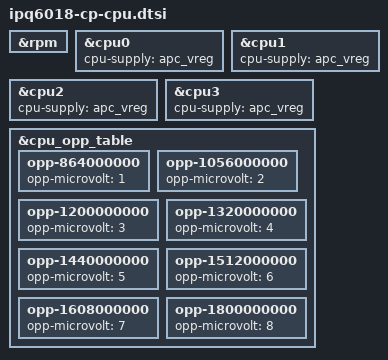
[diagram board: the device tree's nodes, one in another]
// SPDX-License-Identifier: GPL-2.0-or-later OR MIT

#include "ipq6018-cpr-regulator.dtsi"

&rpm {
	status = "okay";
};

&cpu0 {
	cpu-supply = <&apc_vreg>;
};

&cpu1 {
	cpu-supply = <&apc_vreg>;
};

&cpu2 {
	cpu-supply = <&apc_vreg>;
};

&cpu3 {
	cpu-supply = <&apc_vreg>;
};

&cpu_opp_table {
	opp-864000000 {
		opp-microvolt = <1>;
	};

	opp-1056000000 {
		opp-microvolt = <2>;
	};

	opp-1200000000 {
		opp-microvolt = <3>;
	};

	opp-1320000000 {
		opp-microvolt = <4>;
	};

	opp-1440000000 {
		opp-microvolt = <5>;
	};

	opp-1512000000 {
		opp-microvolt = <6>;
	};

	opp-1608000000 {
		opp-microvolt = <7>;
	};

	opp-1800000000 {
		opp-microvolt = <8>;
	};
};
